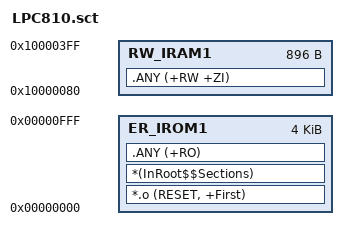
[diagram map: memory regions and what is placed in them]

LR_IROM1 0x00000000 0x1000  {    ; load region size_region (4k)
  ER_IROM1 0x00000000 0x1000  {  ; load address = execution address
   *.o (RESET, +First)
   *(InRoot$$Sections)
   .ANY (+RO)
  }
  ; 8_byte_aligned(32 vect * 4 bytes) = 0x80
  ; 1KB(0x0400) - 0x80 = 0x380
  RW_IRAM1 (0x10000000+0x80) (0x400-0x80)  {
   .ANY (+RW +ZI)
  }
}

